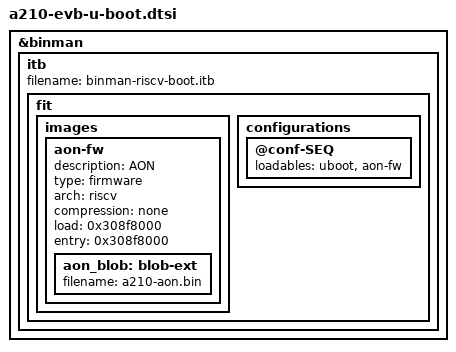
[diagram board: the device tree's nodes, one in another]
// SPDX-License-Identifier: GPL-2.0-only
/*
 * Copyright (c) 2025 Hangfan Li <lihangfan@iscas.ac.cn>
 */

#include <binman.dtsi>

&binman {
	itb {
		filename = "binman-riscv-boot.itb";
		fit {
			images {
				aon-fw {
					description = "AON";
					type = "firmware";
					arch = "riscv";
					compression = "none";
					load = <0x308f8000>;
					entry = <0x308f8000>;

					aon_blob: blob-ext {
						filename = "a210-aon.bin";
					};
				};
			};

			configurations {
				@conf-SEQ {
					loadables = "uboot", "aon-fw";
				};
			};
		};
	};
};
